AUTOSAR XML (schema 4-0-3)
package /ComponentTypes
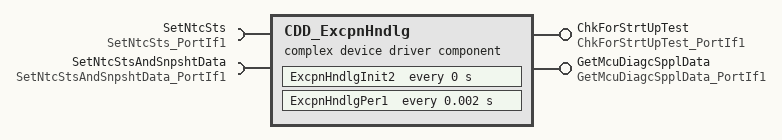
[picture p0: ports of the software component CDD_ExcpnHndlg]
  complex device driver sw component type CDD_ExcpnHndlg
    provide port ChkForStrtUpTest: server-com-spec{operation=Oper, queue-length=1}, provided-interface=ChkForStrtUpTest_PortIf1
    provide port GetMcuDiagcSpplData: server-com-spec{operation=Oper, queue-length=1}, provided-interface=GetMcuDiagcSpplData_PortIf1
    require port SetNtcSts: client-com-spec=Oper, required-interface=SetNtcSts_PortIf1
    require port SetNtcStsAndSnpshtData: client-com-spec=Oper, required-interface=SetNtcStsAndSnpshtData_PortIf1
    behavior CDD_ExcpnHndlg_InternalBehavior
      ar-typed-per-instance-memorys:
        data McuDiagcData: sw-calibration-access=READ-ONLY, type=Ary1D_u32_4
      operation invoked event OIT_ChkForStrtUpTest_Oper_ChkForStrtUpTest_Oper: start-on-event=ChkForStrtUpTest_Oper, operation=ChkForStrtUpTest.Oper
      timing event CDD_ExcpnHndlg_InitEvent: start-on-event=ExcpnHndlgInit2, period=0
      timing event TMT_ExcpnHndlgPer1: start-on-event=ExcpnHndlgPer1, period=0.002
      operation invoked event OIT_GetMcuDiagcSpplData_Oper_GetMcuDiagcSpplData_Oper: start-on-event=GetMcuDiagcSpplData_Oper, operation=GetMcuDiagcSpplData.Oper
      4 x runnable:
        ChkForStrtUpTest_Oper
        ExcpnHndlgInit2
          sync call SC_SetNtcSts_Oper: operation=SetNtcSts.Oper, timeout=0
          sync call SC_SetNtcStsAndSnpshtData_Oper: operation=SetNtcStsAndSnpshtData.Oper, timeout=0
        ExcpnHndlgPer1
          sync call SC_SetNtcStsAndSnpshtData_Oper: operation=SetNtcStsAndSnpshtData.Oper, timeout=0
        GetMcuDiagcSpplData_Oper: can-be-invoked-concurrently=true
  swc implementation CDD_ExcpnHndlg_Implementation: behavior=CDD_ExcpnHndlg_InternalBehavior
    code-descriptors:
      code Default: artifact-descriptors=autosar-engineering-object={short-label=Default, category=SWSRC}
